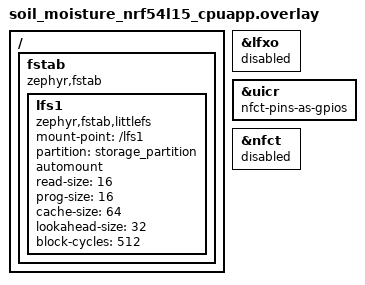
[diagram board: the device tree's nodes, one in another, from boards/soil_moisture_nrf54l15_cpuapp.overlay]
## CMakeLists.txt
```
# Copyright (c) 2025 Golioth, Inc.
#
# SPDX-License-Identifier: Apache-2.0

cmake_minimum_required(VERSION 3.20.0)

# BOARD_ROOT = firmware (board defs in firmware/boards/) for non-sysbuild builds; sysbuild uses sysbuild/CMakeLists.txt
get_filename_component(FW_ROOT ${CMAKE_CURRENT_SOURCE_DIR}/../.. ABSOLUTE)
list(APPEND BOARD_ROOT ${FW_ROOT})

find_package(Zephyr REQUIRED HINTS $ENV{ZEPHYR_BASE})
project(feather_node)

target_sources(app PRIVATE
	src/main.c
	src/credentials.c
	src/fatal_error.c
	src/fw_update.c
	src/ble_peripheral.c
	src/feather_status.c
	src/fuel_gauge.c
)

if(CONFIG_BOARD_NRF54L15_FEATHER)
	target_sources(app PRIVATE src/feather_run5.c)
endif()
```

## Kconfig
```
# Copyright (c) 2025 Golioth, Inc.
#
# SPDX-License-Identifier: Apache-2.0

config NCS_APPLICATION_BOOT_BANNER_STRING
    string
    default "nRF54L15 Feather Pouch node"

source "$ZEPHYR_BASE/Kconfig"

config EXAMPLE_SYNC_PERIOD_S
    int "Sync period in seconds"
    default 300
    help
      Seconds to stay idle after an advertising window or a session before
      asking a gateway for another sync. Long enough that one gateway can
      serve several nodes.

config EXAMPLE_ADV_WINDOW_S
    int "Advertising window in seconds"
    default 30
    help
      How long the gateway-request flag stays set. After this the flag is
      cleared for EXAMPLE_SYNC_PERIOD_S so other Pouch nodes can be chosen.

config EXAMPLE_CREDENTIALS_DIR
    string "Directory containing credentials"
    default "/lfs1/credentials"
    help
      Directory on mounted file system containing credentials.

config EXAMPLE_FW_UPDATE_COMPONENT
    string "OTA component to use for firmware update"
    default "feather_node"
    help
      Name of component in OTA manifest to use for firmware update.

config FEATHER_STATUS_PERIOD_S
    int "nPM1300 / fuel gauge sample period in seconds"
    default 5
    help
      The fuel gauge wants regular samples. The latest snapshot is what
      the next uplink carries.

# This option is used only for automated tests
config EXAMPLE_BT_AUTO_CONFIRM
	bool
	default y if BOARD_NRF52_BSIM_NATIVE
```

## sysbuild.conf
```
# MCUboot (swap). Signed with the MCUboot dev key until a production key is chosen.
SB_CONFIG_BOOTLOADER_MCUBOOT=y
```

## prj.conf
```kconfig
# Copyright (c) 2025 Golioth, Inc.
#
# SPDX-License-Identifier: Apache-2.0
#
# nRF54L15 feather as a Golioth Pouch BLE node (ble_gatt example + solar board fixes).

CONFIG_BT=y
CONFIG_BT_SMP=y
CONFIG_BT_PERIPHERAL=y
CONFIG_BT_DEVICE_NAME="Feather"
CONFIG_BT_DEVICE_APPEARANCE=768

CONFIG_BT_BUF_ACL_TX_SIZE=251
CONFIG_BT_BUF_ACL_RX_SIZE=251
CONFIG_BT_L2CAP_TX_MTU=247

# This allows centrals that connect using Just Works authentication
# to re-pair. This can allow attackers to force a device to forget
# a legitimate bond. In production applications, we recommend using
# authenticated pairing, or if that is not an option, to limit the
# times when pairing is possible (e.g. by requiring user interaction
# to forget bonds or to enter pairing mode).
# We enable this option in the example app because in the absence of
# authenticated connections or another method for forcing the deletion
# of bond data, Centrals that lose their bonding information will be
# unable to reconnect.
CONFIG_BT_SMP_ALLOW_UNAUTH_OVERWRITE=y

# This is needed due to an off-by-one error in Kconfig defaults
CONFIG_BT_CTLR_DATA_LENGTH_MAX=251

CONFIG_BT_RX_STACK_SIZE=4096

CONFIG_MAIN_STACK_SIZE=4096

CONFIG_MBEDTLS_HEAP_SIZE=9192

# This option is implied by BT_SMP and breaks secp384r1 support
CONFIG_MBEDTLS_PSA_P256M_DRIVER_ENABLED=n

# Turn off default options to reduce ROM usage
CONFIG_MBEDTLS_PKCS5_C=n

# No 32.768 kHz crystal (X2 is DNP). Also set in the board defconfig; repeated
# here so the app does not silently depend on the board file.
CONFIG_CLOCK_CONTROL_NRF_K32SRC_RC=y
CONFIG_NRF_GRTC_TIMER_SOURCE_LFLPRC=y

# RTT logs so a J-Link session can show what the firmware is doing.
# The up buffer is large enough to hold a gateway session while the
# viewer is attached. Drop mode does not spin when nothing is reading.
# The shell stays off because its 10 ms RTT poll holds the CPU out of idle.
CONFIG_LOG=y
CONFIG_LOG_MODE_DEFERRED=y
CONFIG_LOG_DEFAULT_LEVEL=3
CONFIG_LOG_BUFFER_SIZE=4096
CONFIG_USE_SEGGER_RTT=y
CONFIG_LOG_BACKEND_RTT=y
CONFIG_LOG_BACKEND_RTT_MODE_DROP=y
CONFIG_SEGGER_RTT_BUFFER_SIZE_UP=8192

# Gateway session detail while debugging. Bluetooth host stays at info.
CONFIG_POUCH_COMMON_LOG_LEVEL_DBG=y
CONFIG_POUCH_GATT_LOG_LEVEL_DBG=y
CONFIG_POUCH_TRANSPORT_LOG_LEVEL_DBG=y
CONFIG_ZCBOR=y
CONFIG_REBOOT=y
CONFIG_SHELL=n

# Keep the debug port open. A locked access port blocks J-Link.
CONFIG_NRF_APPROTECT_DISABLE=y
CONFIG_NRF_SECURE_APPROTECT_DISABLE=y

# Ask a gateway for one sync this often, then clear the request flag
# so other Pouch boards can be chosen. The window is how long the flag stays set.
CONFIG_EXAMPLE_SYNC_PERIOD_S=300
CONFIG_EXAMPLE_ADV_WINDOW_S=30

CONFIG_POUCH=y
CONFIG_POUCH_TRANSPORT_BLE_GATT=y

CONFIG_GOLIOTH=y
CONFIG_GOLIOTH_SETTINGS=y
CONFIG_GOLIOTH_OTA=y

# Enable flash operations
CONFIG_FLASH=y
CONFIG_FLASH_MAP=y

# Enable the LittleFS file system
CONFIG_FILE_SYSTEM=y
CONFIG_FILE_SYSTEM_LITTLEFS=y

# No UART on this board. RTT is the log channel only, not a console.
CONFIG_CONSOLE=n
CONFIG_UART_CONSOLE=n
CONFIG_SERIAL=n
CONFIG_RTT_CONSOLE=n
CONFIG_SHELL_BACKEND_RTT=n
CONFIG_SHELL_BACKEND_SERIAL=n

# MCUmgr over the shell was only for bench provisioning. Pouch OTA uses
# the image manager below, which does not need a shell transport.
CONFIG_MCUMGR=n

CONFIG_STREAM_FLASH=y
CONFIG_IMG_MANAGER=y
CONFIG_IMG_ERASE_PROGRESSIVELY=y

# nPM1300 PMIC (regulators, charger, fuel gauge)
CONFIG_GPIO=y
CONFIG_I2C=y
CONFIG_MFD=y
CONFIG_MFD_NPM13XX=y
CONFIG_REGULATOR=y
CONFIG_REGULATOR_NPM13XX=y
CONFIG_SENSOR=y
CONFIG_NPM13XX_CHARGER=y
CONFIG_NRF_FUEL_GAUGE=y
CONFIG_NRF_FUEL_GAUGE_VARIANT_SECONDARY_CELL=y
```

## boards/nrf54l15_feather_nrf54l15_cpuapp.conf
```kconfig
# Feather run 5: SAADC for SENS_ID (P1.06). GPIO hogs are enabled automatically by the
# ant-sel-hog node in the board dts.
CONFIG_ADC=y
CONFIG_GPIO_HOGS=y
```

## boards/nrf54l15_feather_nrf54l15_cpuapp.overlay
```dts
/* Pouch credentials live on LittleFS in the storage partition (RRAM 0x174000, 36 KB). */
/ {
	fstab {
		compatible = "zephyr,fstab";
		lfs1: lfs1 {
			compatible = "zephyr,fstab,littlefs";
			mount-point = "/lfs1";
			partition = <&storage_partition>;
			automount;
			read-size = <16>;
			prog-size = <16>;
			cache-size = <64>;
			lookahead-size = <32>;
			block-cycles = <512>;
		};
	};
};
```

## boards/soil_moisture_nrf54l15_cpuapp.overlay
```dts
/* Pouch credentials live on LittleFS in the storage partition. */
/ {
	fstab {
		compatible = "zephyr,fstab";
		lfs1: lfs1 {
			compatible = "zephyr,fstab,littlefs";
			mount-point = "/lfs1";
			partition = <&storage_partition>;
			automount;
			read-size = <16>;
			prog-size = <16>;
			cache-size = <64>;
			lookahead-size = <32>;
			block-cycles = <512>;
		};
	};
};

/* The soil_moisture board file predates these fixes (see the feather board file):
 * no 32 kHz crystal, and SCL on P1.03 is an NFC pin.
 */
&lfxo {
	status = "disabled";
};

&uicr {
	nfct-pins-as-gpios;
};

&nfct {
	status = "disabled";
};
```

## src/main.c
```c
/*
 * Copyright (c) 2025 Golioth
 *
 * SPDX-License-Identifier: Apache-2.0
 *
 * nRF54L15 feather as a Golioth Pouch BLE node. Based on the Pouch ble_gatt
 * example and the nrf54l15_solar_pouch app.
 */

#include <zephyr/logging/log.h>
LOG_MODULE_REGISTER(main);

#include "credentials.h"
#include "ble_peripheral.h"
#include "feather_status.h"

#ifdef CONFIG_BOARD_NRF54L15_FEATHER
#include "feather_run5.h"
#endif

#include <zephyr/kernel.h>
#include <zephyr/drivers/gpio.h>
#include <zephyr/drivers/mfd/npm13xx.h>

#include <pouch/pouch.h>
#include <pouch/events.h>
#include <pouch/uplink.h>
#include <pouch/downlink.h>
#include <pouch/transport/bluetooth/gatt.h>

#include <golioth/settings_callbacks.h>

#include <app_version.h>

static const struct device *pmic = DEVICE_DT_GET_OR_NULL(DT_NODELABEL(npm1300_ek_pmic));
static const struct gpio_dt_spec button = GPIO_DT_SPEC_GET_OR(DT_ALIAS(sw0), gpios, {});

/* nPM1300 LEDDRV. CLR turns the pin off only while the mode is host. */
#define NPM_LED_BASE      0x0AU
#define NPM_LED_MODE_HOST 2U
#define NPM_LED_CLR       1U
static struct gpio_callback button_cb_data;

/**
 * Push timeseries application data to the cloud on every uplink
 */
static void do_uplink(void)
{
	char json[256];
	int len = feather_status_format(json, sizeof(json));

	if (len < 0) {
		LOG_ERR("Status format failed (%d)", len);
		return;
	}

	LOG_INF("Uplink %s", json);

	int err = pouch_uplink_entry_write(".s/sensor", POUCH_CONTENT_TYPE_JSON, json, (size_t)len,
					   POUCH_FOREVER);
	if (err) {
		LOG_ERR("Uplink write failed (%d)", err);
	}
}

POUCH_UPLINK_HANDLER(do_uplink);

/**
 * Settings handler for the "LED" setting. The feather keeps its LED off,
 * lighting it costs 5 mA.
 */
static int led_setting_cb(bool new_value)
{
	ARG_UNUSED(new_value);
	return 0;
}

GOLIOTH_SETTINGS_HANDLER(LED, led_setting_cb);

static void pouch_event(enum pouch_event event, void *ctx)
{
	ARG_UNUSED(ctx);

	if (event == POUCH_EVENT_SESSION_START) {
		LOG_INF("Pouch session started");
	} else if (event == POUCH_EVENT_SESSION_END) {
		LOG_INF("Pouch session ended");
	}
}

POUCH_EVENT_HANDLER(pouch_event, NULL);

/**
 * Setup pouch stack: load credentials and initialize pouch.
 */
static int setup_pouch(void)
{
	struct pouch_config config = {0};

	int err = load_certificate(&config.certificate);
	if (err) {
		LOG_ERR("Failed to load certificate (err %d)", err);
		return err;
	}

	config.private_key = load_private_key();
	if (config.private_key == PSA_KEY_ID_NULL) {
		LOG_ERR("Failed to load private key");
		return -ENOENT;
	}

	LOG_INF("Credentials loaded");

	err = pouch_init(&config);
	if (err) {
		LOG_ERR("Pouch init failed (err %d)", err);
		return err;
	}

	LOG_INF("Pouch initialized");
	return 0;
}

/**
 * Turn the nPM1300 LEDs off. The PMIC stays powered when the nRF resets, so a
 * host "on" bit survives. CLR is ignored unless the mode is host.
 */
static void setup_led(void)
{
	if (!device_is_ready(pmic)) {
		LOG_WRN("nPM1300 is not ready");
		return;
	}

	for (uint8_t led = 0; led < 3; led++) {
		int err = mfd_npm13xx_reg_write(pmic, NPM_LED_BASE, led, NPM_LED_MODE_HOST);

		if (err == 0) {
			err = mfd_npm13xx_reg_write(pmic, NPM_LED_BASE, 0x04U + (led * 2U),
						    NPM_LED_CLR);
		}

		if (err < 0) {
			LOG_WRN("Could not turn off nPM1300 LED %u (err %d)", led, err);
		}
	}
}

/**
 * Button handler for the Bluetooth OOB authentication mechanism.
 */
static void button_pressed(const struct device *dev, struct gpio_callback *cb, uint32_t pins)
{
	ble_peripheral_button_handler();
}

/**
 * Initialize the button (alias sw0). The feather has SW1 on the board but it
 * is not in the devicetree yet, so this is skipped.
 */
static void setup_button(void)
{
	if (!DT_HAS_ALIAS(sw0) || !DT_NODE_HAS_STATUS(DT_ALIAS(sw0), okay)) {
		return;
	}

	LOG_INF("Set up button at %s pin %d", button.port->name, button.pin);

	int err = gpio_pin_configure_dt(&button, GPIO_INPUT);
	if (err < 0) {
		LOG_WRN("Could not initialize Button");
		return;
	}

	err = gpio_pin_interrupt_configure_dt(&button, GPIO_INT_EDGE_TO_ACTIVE);
	if (err) {
		LOG_WRN("Error %d: failed to configure interrupt on %s pin %d", err,
			button.port->name, button.pin);
		return;
	}

	gpio_init_callback(&button_cb_data, button_pressed, BIT(button.pin));
	gpio_add_callback(button.port, &button_cb_data);
}

int main(void)
{
#ifdef CONFIG_BOARD_NRF54L15_FEATHER
	/* VRF (LDSW2) comes up in the regulator driver init, after the ANT_SEL gpio-hog. */
	(void)feather_vrf_check();
#endif

	feather_status_start();
	setup_led();

	LOG_INF("Pouch SDK Version: " STRINGIFY(APP_BUILD_VERSION));
	LOG_INF("Pouch Protocol Version: %d", POUCH_VERSION);
	LOG_INF("Pouch BLE Transport Protocol Version: %d", POUCH_GATT_VERSION);

	int err = ble_peripheral_init();
	if (err) {
		return err;
	}

	err = setup_pouch();
	if (err) {
		LOG_ERR("Pouch is not running (err %d). Still advertising so the gateway attempt is visible.",
			err);
	}

	setup_button();

	err = ble_peripheral_start();
	if (err) {
		LOG_ERR("Advertising failed (err %d)", err);
	}

	/* Stay awake and keep printing. Returning here would idle with no further logs. */
	while (1) {
		k_sleep(K_SECONDS(10));
		if (err) {
			LOG_ERR("Up, advertising is not running");
		} else if (ble_peripheral_sync_requested()) {
			LOG_INF("Up, requesting a gateway");
		} else {
			LOG_INF("Up, gateway request is off");
		}
	}
}
```

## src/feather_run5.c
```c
#include <zephyr/kernel.h>
#include <zephyr/device.h>
#include <zephyr/drivers/adc.h>
#include <zephyr/drivers/gpio.h>
#include <zephyr/drivers/regulator.h>
#include <zephyr/logging/log.h>

#include "feather_run5.h"

LOG_MODULE_REGISTER(feather, LOG_LEVEL_INF);

/* nPM1300 LDO1 node = LDSW1 = VSENS, LDO2 node = LDSW2 = VRF (see the board dts). */
static const struct device *const vsens = DEVICE_DT_GET(DT_NODELABEL(npm1300_ek_ldo1));
static const struct device *const vrf = DEVICE_DT_GET(DT_NODELABEL(npm1300_ek_ldo2));
static const struct gpio_dt_spec ant_sel = GPIO_DT_SPEC_GET(DT_ALIAS(ant_sel), gpios);
static const struct adc_dt_spec sens_id = ADC_DT_SPEC_GET_BY_IDX(DT_PATH(zephyr_user), 0);

/* R19 pull-up on SENS_ID to VSENS, nominal VSENS (VDDIO via LSIN1, load switch mode). */
#define SENS_ID_PULLUP_OHM 100000 /* was 10k until the 2026-11-11 x10 rescale */
#define VSENS_NOMINAL_MV   3000
/* Settling time after VSENS on before sampling (load switch ramp + C45 + sensor board).
 * The ID divider now has about 50-70k source impedance, so any capacitance on SENS_ID
 * (100 nF assumed worst case) gives tau of 5-7 ms; 50 ms is about 7 tau. */
#define VSENS_SETTLE_MS    50
/* Above this fraction of VSENS the pin is treated as open (no sensor board). */
#define SENS_ID_OPEN_MV    2900

int feather_vrf_check(void)
{
	int32_t uv = 0;
	int err;

	if (!device_is_ready(vrf)) {
		LOG_ERR("VRF regulator not ready");
		return -ENODEV;
	}

	if (!regulator_is_enabled(vrf)) {
		LOG_ERR("VRF (LDSW2) is not enabled");
		return -EIO;
	}

	err = regulator_get_voltage(vrf, &uv);
	if (err) {
		LOG_ERR("VRF get voltage failed (%d)", err);
		return err;
	}

	LOG_INF("VRF on, %d mV", uv / 1000);

	if (uv != 2500000) {
		LOG_WRN("VRF is not 2.5 V");
		return -EINVAL;
	}

	/* ANT_SEL was driven low by the gpio-hog before VRF came up. Report the level. */
	if (gpio_is_ready_dt(&ant_sel)) {
		LOG_INF("ANT_SEL (P0.01) reads %d (0 = chip antenna)",
			gpio_pin_get_raw(ant_sel.port, ant_sel.pin));
	}

	return 0;
}

int feather_read_sens_id(int32_t *pin_mv, uint32_t *rid_ohm)
{
	int16_t raw = 0;
	int32_t mv;
	int err;
	struct adc_sequence seq = {
		.buffer = &raw,
		.buffer_size = sizeof(raw),
	};

	if (!device_is_ready(vsens) || !adc_is_ready_dt(&sens_id)) {
		return -ENODEV;
	}

	err = adc_channel_setup_dt(&sens_id);
	if (err) {
		return err;
	}

	err = adc_sequence_init_dt(&sens_id, &seq);
	if (err) {
		return err;
	}

	err = regulator_enable(vsens);
	if (err) {
		LOG_ERR("VSENS enable failed (%d)", err);
		return err;
	}

	k_msleep(VSENS_SETTLE_MS);

	err = adc_read_dt(&sens_id, &seq);

	/* Always switch VSENS off again; SENS_ID is only valid while VSENS is on. */
	(void)regulator_disable(vsens);

	if (err) {
		LOG_ERR("SENS_ID ADC read failed (%d)", err);
		return err;
	}

	mv = raw;
	err = adc_raw_to_millivolts_dt(&sens_id, &mv);
	if (err) {
		return err;
	}

	*pin_mv = mv;
	if (mv >= SENS_ID_OPEN_MV) {
		*rid_ohm = 0;
	} else if (mv <= 0) {
		*rid_ohm = 0; /* shorted: also not a valid ID */
	} else {
		*rid_ohm = (uint32_t)(((int64_t)SENS_ID_PULLUP_OHM * mv) /
				      (VSENS_NOMINAL_MV - mv));
	}

	return 0;
}
```

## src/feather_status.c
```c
#include "feather_status.h"

#include <zephyr/kernel.h>
#include <zephyr/device.h>
#include <zephyr/drivers/sensor.h>
#include <zephyr/drivers/sensor/npm13xx_charger.h>
#include <zephyr/logging/log.h>
#include <zephyr/sys/printk.h>

#include "fuel_gauge.h"

#ifdef CONFIG_BOARD_NRF54L15_FEATHER
#include "feather_run5.h"
#endif

LOG_MODULE_REGISTER(feather_status, LOG_LEVEL_INF);

#define CHARGER_NODE DT_NODELABEL(npm1300_ek_charger)

#define CHG_STATUS_COMPLETE BIT(1)
#define CHG_STATUS_TRICKLE  BIT(2)
#define CHG_STATUS_CC       BIT(3)
#define CHG_STATUS_CV       BIT(4)
#define VBUS_PRESENT        BIT(0)

/* A LiPo voltage on VBAT means a cell is fitted even while the charger is idle. */
#define VBAT_PRESENT_MIN_MV 2500
#define VBAT_PRESENT_MAX_MV 4500

#define SENS_ID_REFRESH_SAMPLES 12 /* about once a minute at the default period */

#define STATUS_STACK_SIZE 2048
#define STATUS_PRIORITY   10

struct feather_snapshot {
	uint16_t vbat_mv;
	int16_t soc_pct; /* -1 when the fuel gauge did not start */
	int16_t ibat_ma; /* Zephyr sign: negative = discharging */
	const char *charge;
	bool vbus;
	int32_t sens_id_mv; /* -1 when not read */
	int32_t sens_rid_ohm; /* 0 = open (no sensor board) or invalid, -1 when not read */
};

static const struct device *charger = DEVICE_DT_GET(CHARGER_NODE);
static struct k_mutex snap_lock;
static struct feather_snapshot snap = {
	.soc_pct = -1,
	.charge = "NO-BATT",
	.sens_id_mv = -1,
	.sens_rid_ohm = -1,
};
static bool gauge_ok;
static uint32_t sample_count;

K_KERNEL_STACK_DEFINE(status_stack, STATUS_STACK_SIZE);
static struct k_work_q status_wq;
static struct k_work_delayable sample_work;

static const char *charge_str(int32_t status, uint16_t vbat_mv)
{
	if (status & CHG_STATUS_COMPLETE) {
		return "COMPLETE";
	}
	if (status & CHG_STATUS_CV) {
		return "CV";
	}
	if (status & CHG_STATUS_CC) {
		return "CC";
	}
	if (status & CHG_STATUS_TRICKLE) {
		return "TRICKLE";
	}
	if ((vbat_mv >= VBAT_PRESENT_MIN_MV) && (vbat_mv <= VBAT_PRESENT_MAX_MV)) {
		return "IDLE";
	}
	return "NO-BATT";
}

static void read_sens_id(struct feather_snapshot *next)
{
#ifdef CONFIG_BOARD_NRF54L15_FEATHER
	int32_t id_mv;
	uint32_t rid;

	/* Switches VSENS on for about 50 ms, so only do it now and then. */
	if (feather_read_sens_id(&id_mv, &rid) == 0) {
		next->sens_id_mv = id_mv;
		next->sens_rid_ohm = (int32_t)rid;
		LOG_INF("SENS_ID %d mV, Rid about %u ohm (0 = open or invalid)", id_mv, rid);
	}
#else
	ARG_UNUSED(next);
#endif
}

static void sample_handler(struct k_work *work)
{
	struct sensor_value vbus = {0};
	struct fuel_gauge_sample fg = {0};
	struct feather_snapshot next;
	int32_t mv;
	int32_t ma;
	bool vbus_on;

	ARG_UNUSED(work);

	k_work_schedule_for_queue(&status_wq, &sample_work,
				  K_SECONDS(CONFIG_FEATHER_STATUS_PERIOD_S));

	k_mutex_lock(&snap_lock, K_FOREVER);
	next = snap;
	k_mutex_unlock(&snap_lock);

	if (!device_is_ready(charger)) {
		LOG_ERR("nPM1300 charger not ready");
		return;
	}

	if (sensor_sample_fetch(charger) < 0) {
		LOG_ERR("nPM1300 sample fetch failed");
		return;
	}
	sensor_channel_get(charger, SENSOR_CHAN_NPM13XX_CHARGER_VBUS_STATUS, &vbus);
	vbus_on = (vbus.val1 & VBUS_PRESENT) != 0;

	if (!gauge_ok && (fuel_gauge_init(charger) == 0)) {
		gauge_ok = true;
	}
	fg.soc = -1.f;
	if ((gauge_ok ? fuel_gauge_update(charger, vbus_on, &fg) :
			fuel_gauge_read(charger, &fg)) < 0) {
		LOG_ERR("Fuel gauge update failed");
		return;
	}

	mv = (int32_t)(fg.voltage * 1000.f + 0.5f);
	ma = (int32_t)(fg.current * 1000.f);

	next.vbat_mv = (uint16_t)CLAMP(mv, 0, UINT16_MAX);
	next.ibat_ma = (int16_t)CLAMP(ma, INT16_MIN, INT16_MAX);
	next.vbus = vbus_on;
	next.charge = charge_str(fg.chg_status, next.vbat_mv);
	next.soc_pct = (fg.soc < 0.f) ? -1 : (int16_t)CLAMP((int32_t)(fg.soc + 0.5f), 0, 100);

	if ((sample_count++ % SENS_ID_REFRESH_SAMPLES) == 0) {
		read_sens_id(&next);
	}

	k_mutex_lock(&snap_lock, K_FOREVER);
	snap = next;
	k_mutex_unlock(&snap_lock);

	LOG_INF("VBAT %u mV (%d%%) I %+d mA %s VBUS %s", next.vbat_mv, next.soc_pct,
		next.ibat_ma, next.charge, next.vbus ? "yes" : "no");
}

void feather_status_start(void)
{
	k_mutex_init(&snap_lock);

	if (!device_is_ready(charger)) {
		LOG_ERR("nPM1300 charger not ready, no battery data");
	} else if (fuel_gauge_init(charger) < 0) {
		LOG_ERR("Could not initialise fuel gauge");
	} else {
		gauge_ok = true;
	}

	k_work_queue_start(&status_wq, status_stack, K_KERNEL_STACK_SIZEOF(status_stack),
			   STATUS_PRIORITY, NULL);
	k_work_init_delayable(&sample_work, sample_handler);
	k_work_schedule_for_queue(&status_wq, &sample_work, K_NO_WAIT);
}

int feather_status_format(char *buf, size_t len)
{
	struct feather_snapshot copy;
	int wrote;

	if ((buf == NULL) || (len == 0U)) {
		return -EINVAL;
	}

	k_mutex_lock(&snap_lock, K_FOREVER);
	copy = snap;
	k_mutex_unlock(&snap_lock);

	wrote = snprintk(buf, len,
			 "{\"vbat_mv\":%u,\"soc_pct\":%d,\"ibat_ma\":%d,"
			 "\"charge\":\"%s\",\"vbus\":%s,"
			 "\"sens_id_mv\":%d,\"sens_rid_ohm\":%d}",
			 copy.vbat_mv, copy.soc_pct, copy.ibat_ma, copy.charge,
			 copy.vbus ? "true" : "false", (int)copy.sens_id_mv,
			 (int)copy.sens_rid_ohm);
	if ((wrote < 0) || ((size_t)wrote >= len)) {
		return -ENOMEM;
	}
	return wrote;
}
```

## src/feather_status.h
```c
#ifndef FEATHER_STATUS_H_
#define FEATHER_STATUS_H_

#include <stddef.h>

/* Start the nPM1300 / fuel gauge sampling thread and read SENS_ID once.
 * Sampling runs on its own work queue so the gateway request window in
 * ble_peripheral.c keeps running between syncs.
 */
void feather_status_start(void);

/* Write the latest snapshot as one JSON object (vbat_mv, soc_pct, ibat_ma,
 * charge, vbus, sens_id_mv, sens_rid_ohm). Returns the length written,
 * excluding the terminating NUL, or a negative errno.
 */
int feather_status_format(char *buf, size_t len);

#endif /* FEATHER_STATUS_H_ */
```

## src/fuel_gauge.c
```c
/*
 * Copyright (c) 2023 Nordic Semiconductor ASA
 * SPDX-License-Identifier: LicenseRef-Nordic-5-Clause
 */

#include <math.h>
#include <stdlib.h>

#include <zephyr/kernel.h>
#include <zephyr/device.h>
#include <zephyr/drivers/sensor.h>
#include <zephyr/drivers/sensor/npm13xx_charger.h>
#include <zephyr/logging/log.h>
#include <zephyr/sys/util.h>

#include <nrf_fuel_gauge.h>

#include "fuel_gauge.h"

LOG_MODULE_REGISTER(fuel_gauge, LOG_LEVEL_INF);

/* nPM13xx CHARGER.BCHGCHARGESTATUS register bitmasks */
#define NPM13XX_CHG_STATUS_COMPLETE_MASK BIT(1)
#define NPM13XX_CHG_STATUS_TRICKLE_MASK  BIT(2)
#define NPM13XX_CHG_STATUS_CC_MASK       BIT(3)
#define NPM13XX_CHG_STATUS_CV_MASK       BIT(4)

static int64_t ref_time;

static const struct battery_model battery_model = {
#if DT_NODE_EXISTS(DT_NODELABEL(npm1300_ek_pmic))
#include "battery_model.inc"
#elif DT_NODE_EXISTS(DT_NODELABEL(npm1304_ek_pmic))
#include "battery_model_20mAh.inc"
#endif
};

static int read_sensors(const struct device *charger, float *voltage, float *current, float *temp,
			int32_t *chg_status)
{
	struct sensor_value value;
	int ret;

	ret = sensor_sample_fetch(charger);
	if (ret < 0) {
		return ret;
	}

	sensor_channel_get(charger, SENSOR_CHAN_GAUGE_VOLTAGE, &value);
	*voltage = (float)value.val1 + ((float)value.val2 / 1000000);

	sensor_channel_get(charger, SENSOR_CHAN_GAUGE_TEMP, &value);
	*temp = (float)value.val1 + ((float)value.val2 / 1000000);

	sensor_channel_get(charger, SENSOR_CHAN_GAUGE_AVG_CURRENT, &value);
	*current = (float)value.val1 + ((float)value.val2 / 1000000);

	sensor_channel_get(charger, SENSOR_CHAN_NPM13XX_CHARGER_STATUS, &value);
	*chg_status = value.val1;

	return 0;
}

static int charge_status_inform(int32_t chg_status)
{
	union nrf_fuel_gauge_ext_state_info_data state_info;

	if (chg_status & NPM13XX_CHG_STATUS_COMPLETE_MASK) {
		LOG_INF("Charge complete");
		state_info.charge_state = NRF_FUEL_GAUGE_CHARGE_STATE_COMPLETE;
	} else if (chg_status & NPM13XX_CHG_STATUS_TRICKLE_MASK) {
		LOG_INF("Trickle charging");
		state_info.charge_state = NRF_FUEL_GAUGE_CHARGE_STATE_TRICKLE;
	} else if (chg_status & NPM13XX_CHG_STATUS_CC_MASK) {
		LOG_INF("Constant current charging");
		state_info.charge_state = NRF_FUEL_GAUGE_CHARGE_STATE_CC;
	} else if (chg_status & NPM13XX_CHG_STATUS_CV_MASK) {
		LOG_INF("Constant voltage charging");
		state_info.charge_state = NRF_FUEL_GAUGE_CHARGE_STATE_CV;
	} else {
		LOG_INF("Charger idle");
		state_info.charge_state = NRF_FUEL_GAUGE_CHARGE_STATE_IDLE;
	}

	return nrf_fuel_gauge_ext_state_update(NRF_FUEL_GAUGE_EXT_STATE_INFO_CHARGE_STATE_CHANGE,
					       &state_info);
}

int fuel_gauge_init(const struct device *charger)
{
	struct sensor_value value;
	struct nrf_fuel_gauge_init_parameters parameters = {
		.model = &battery_model,
		.opt_params = NULL,
		.state = NULL,
	};
	float max_charge_current;
	float term_charge_current;
	int32_t chg_status;
	int ret;

	LOG_INF("nRF Fuel Gauge version: %s", nrf_fuel_gauge_version);

	ret = read_sensors(charger, &parameters.v0, &parameters.i0, &parameters.t0, &chg_status);
	if (ret < 0) {
		return ret;
	}
	/* Zephyr sensor API convention for Gauge current is negative=discharging,
	 * while nrf_fuel_gauge lib expects the opposite negative=charging
	 */
	parameters.i0 = -parameters.i0;

	/* Store charge nominal and termination current, needed for ttf calculation */
	sensor_channel_get(charger, SENSOR_CHAN_GAUGE_DESIRED_CHARGING_CURRENT, &value);
	max_charge_current = (float)value.val1 + ((float)value.val2 / 1000000);
	term_charge_current = max_charge_current / 10.f;

	ret = nrf_fuel_gauge_init(&parameters, NULL);
	if (ret < 0) {
		LOG_ERR("Could not initialise fuel gauge");
		return ret;
	}

	ret = nrf_fuel_gauge_ext_state_update(NRF_FUEL_GAUGE_EXT_STATE_INFO_CHARGE_CURRENT_LIMIT,
					      &(union nrf_fuel_gauge_ext_state_info_data){
						      .charge_current_limit = max_charge_current});
	if (ret < 0) {
		LOG_ERR("Could not set fuel gauge state");
		return ret;
	}

	ret = nrf_fuel_gauge_ext_state_update(NRF_FUEL_GAUGE_EXT_STATE_INFO_TERM_CURRENT,
					      &(union nrf_fuel_gauge_ext_state_info_data){
						      .charge_term_current = term_charge_current});
	if (ret < 0) {
		LOG_ERR("Could not set fuel gauge state");
		return ret;
	}

	ret = charge_status_inform(chg_status);
	if (ret < 0) {
		LOG_ERR("Could not set fuel gauge state");
		return ret;
	}

	ref_time = k_uptime_get();

	return 0;
}

int fuel_gauge_read(const struct device *charger, struct fuel_gauge_sample *out)
{
	return read_sensors(charger, &out->voltage, &out->current, &out->temp, &out->chg_status);
}

int fuel_gauge_update(const struct device *charger, bool vbus_connected,
		      struct fuel_gauge_sample *out)
{
	static int32_t chg_status_prev;

	struct fuel_gauge_sample smp;
	float tte;
	float ttf;
	float delta;
	float current;
	int ret;

	ret = read_sensors(charger, &smp.voltage, &smp.current, &smp.temp, &smp.chg_status);
	if (ret < 0) {
		LOG_ERR("Could not read from charger device");
		return ret;
	}
	/* Zephyr sensor API convention for Gauge current is negative=discharging,
	 * while nrf_fuel_gauge lib expects the opposite negative=charging
	 */
	current = -smp.current;

	ret = nrf_fuel_gauge_ext_state_update(
		vbus_connected ? NRF_FUEL_GAUGE_EXT_STATE_INFO_VBUS_CONNECTED
			       : NRF_FUEL_GAUGE_EXT_STATE_INFO_VBUS_DISCONNECTED,
		NULL);
	if (ret < 0) {
		LOG_ERR("Could not inform of state");
		return ret;
	}

	if (smp.chg_status != chg_status_prev) {
		chg_status_prev = smp.chg_status;

		ret = charge_status_inform(smp.chg_status);
		if (ret < 0) {
			LOG_ERR("Could not inform of charge status");
			return ret;
		}
	}

	delta = (float)k_uptime_delta(&ref_time) / 1000.f;

	/* NCS v3.4: process/TTE/TTF return a status and give the value through a pointer. */
	ret = nrf_fuel_gauge_process(smp.voltage, current, smp.temp, delta, &smp.soc, NULL);
	if (ret < 0) {
		LOG_ERR("Fuel gauge process failed");
		return ret;
	}
	if (nrf_fuel_gauge_tte_get(&tte) < 0) {
		tte = NAN;
	}
	if (nrf_fuel_gauge_ttf_get(&ttf) < 0) {
		ttf = NAN;
	}

	/* Integer logging: no float printf in the Pouch build. */
	LOG_INF("V %d mV, I %d mA, T %d.%02d C, SoC %d.%02d %%, TTE %d s, TTF %d s",
		(int)(smp.voltage * 1000.f), (int)(smp.current * 1000.f), (int)smp.temp,
		(int)((smp.temp - (int)smp.temp) * 100.f), (int)smp.soc,
		(int)((smp.soc - (int)smp.soc) * 100.f), isnan(tte) ? -1 : (int)tte, isnan(ttf) ? -1 : (int)ttf);

	if (out != NULL) {
		*out = smp;
	}

	return 0;
}
```

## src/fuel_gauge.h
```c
/*
 * Copyright (c) 2023 Nordic Semiconductor ASA
 * SPDX-License-Identifier: LicenseRef-Nordic-5-Clause
 */

#ifndef __FUEL_GAUGE_H__
#define __FUEL_GAUGE_H__

#include <stdbool.h>
#include <stdint.h>

struct device;

struct fuel_gauge_sample {
	float voltage;     /* V */
	float current;     /* A, Zephyr sign: negative = discharging */
	float temp;        /* degC */
	float soc;         /* percent, -1 when no fuel gauge result */
	int32_t chg_status; /* nPM13xx BCHGCHARGESTATUS */
};

int fuel_gauge_init(const struct device *charger);

/* Fetch and run the gauge. out may be NULL. */
int fuel_gauge_update(const struct device *charger, bool vbus_connected,
		      struct fuel_gauge_sample *out);

/* Fetch only (voltage, current, temp, status); out->soc is not touched. */
int fuel_gauge_read(const struct device *charger, struct fuel_gauge_sample *out);

#endif /* __FUEL_GAUGE_H__ */
```

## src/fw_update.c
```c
/*
 * Copyright (c) 2025 Golioth
 *
 * SPDX-License-Identifier: Apache-2.0
 *
 * Based on golioth/pouch examples/zephyr/ble_gatt/src/fw_update.c at 32ded9b. Changes:
 *  - the upgrade is requested in TEST mode (BOOT_UPGRADE_TEST), not PERMANENT. Upstream never
 *    confirms anything, and a permanent upgrade can never be reverted, even if the new image
 *    cannot reach the cloud any more;
 *  - the new image confirms itself (boot_write_img_confirmed) after one Pouch sync in which the
 *    cloud answered: a downlink was authenticated and decoded (the OTA manifest arrived) and the
 *    session then ended. If that never happens MCUboot reverts at the next reset;
 *  - no new download is started while the running image is still unconfirmed.
 */

#include <zephyr/logging/log.h>
LOG_MODULE_REGISTER(fw_update);

#include <zephyr/kernel.h>
#include <zephyr/dfu/flash_img.h>
#include <zephyr/dfu/mcuboot.h>
#include <zephyr/logging/log_ctrl.h>
#include <zephyr/storage/flash_map.h>
#include <zephyr/sys/reboot.h>

#include <golioth/ota.h>
#include <pouch/events.h>

#include <app_version.h>

static struct flash_img_context flash_context;

/* Set when the cloud answered in this boot (OTA manifest received and decoded). */
static atomic_t cloud_answered;

static void confirm_work_fn(struct k_work *work)
{
    ARG_UNUSED(work);

    if (boot_is_img_confirmed())
    {
        return;
    }

    int err = boot_write_img_confirmed();

    if (err)
    {
        LOG_ERR("Failed to confirm the running image: %d", err);
        return;
    }

    LOG_INF("Image confirmed (version " APP_VERSION_STRING ")");
}

static K_WORK_DEFINE(confirm_work, confirm_work_fn);

/* POUCH_EVENT_SESSION_END fires for failed sessions too (32ded9b drops the transport's success
 * flag), so it only counts together with cloud_answered. Confirm from the system work queue,
 * not from the Pouch thread.
 */
static void pouch_event(enum pouch_event event, void *ctx)
{
    ARG_UNUSED(ctx);

    if (event == POUCH_EVENT_SESSION_END && atomic_get(&cloud_answered)
        && !boot_is_img_confirmed())
    {
        k_work_submit(&confirm_work);
    }
}

POUCH_EVENT_HANDLER(pouch_event, NULL);

static void ota_fw_receive(const void *data, size_t offset, size_t len, bool is_last)
{
    LOG_DBG("Received %d bytes at offset %d", len, offset);

    int err = 0;

    if (0 == offset)
    {
        err = flash_img_init(&flash_context);
        if (err)
        {
            LOG_ERR("Failed to init flash write");
            return;
        }
    }

    err = flash_img_buffered_write(&flash_context, data, len, is_last);
    if (err)
    {
        LOG_ERR("Failed to write to flash: %d", err);
        return;
    }

    if (is_last)
    {
        /* Test mode: MCUboot boots the new image once and reverts at the next reset unless the
         * new image confirms itself (see pouch_event above).
         */
        err = boot_request_upgrade(BOOT_UPGRADE_TEST);
        if (err)
        {
            LOG_ERR("Failed to request upgrade");
            return;
        }

        LOG_INF("Rebooting to apply upgrade");

#if IS_ENABLED(CONFIG_LOG)
        while (log_process())
        {
        }
#endif

        k_sleep(K_SECONDS(3));

        sys_reboot(SYS_REBOOT_WARM);
    }
}

static void ota_manifest_receive(const struct golioth_ota_manifest_component *components,
                                 size_t num_components)
{
    atomic_set(&cloud_answered, 1);

    for (int i = 0; i < num_components; i++)
    {
        LOG_DBG("Target: %s@%s, %d bytes",
                components[i].name,
                components[i].target,
                components[i].size);
        LOG_HEXDUMP_DBG(components[i].target_hash,
                        GOLIOTH_OTA_COMPONENT_HASH_BIN_LEN,
                        "Target hash:");
        if (0 != strcmp(components[i].current, components[i].target))
        {
            if (!boot_is_img_confirmed())
            {
                /* A new upgrade request on top of an unconfirmed image would make MCUboot
                 * revert the running image first. Confirm (end of this session), then update.
                 */
                LOG_WRN("Update to %s postponed: running image not confirmed yet",
                        components[i].target);
                continue;
            }
            golioth_ota_mark_for_download(components[i].name);
        }
    }
}

GOLIOTH_OTA_COMPONENT(fw, CONFIG_EXAMPLE_FW_UPDATE_COMPONENT, APP_VERSION_STRING, ota_fw_receive);
GOLIOTH_OTA_MANIFEST_HANDLER(ota_manifest_receive);
```
